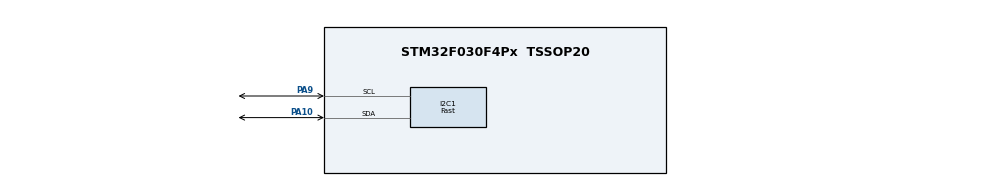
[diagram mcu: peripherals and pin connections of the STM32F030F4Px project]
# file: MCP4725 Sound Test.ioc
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I2C1.I2C_Speed_Mode=I2C_Fast
I2C1.Timing=0x0000020B
Mcu.Family=STM32F0
Mcu.Name=STM32F030F4Px
Mcu.Package=TSSOP20
PA10.Mode=I2C
PA10.Signal=I2C1_SDA
PA9.Mode=I2C
PA9.Signal=I2C1_SCL
ProjectManager.HeapSize=0x200
ProjectManager.StackSize=0x400
ProjectManager.TargetToolchain=SW4STM32
TIM3.Period=999
VP_TIM3_VS_ClockSourceINT.Mode=Internal
board=custom

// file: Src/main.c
/**
  ******************************************************************************
  * @file           : main.c
  * @brief          : Main program body
  ******************************************************************************
  ** This notice applies to any and all portions of this file
  * that are not between comment pairs USER CODE BEGIN and
  * USER CODE END. Other portions of this file, whether
  * inserted by the user or by software development tools
  * are owned by their respective copyright owners.
  *
  * COPYRIGHT(c) 2019 STMicroelectronics
  *
  * Redistribution and use in source and binary forms, with or without modification,
  * are permitted provided that the following conditions are met:
  *   1. Redistributions of source code must retain the above copyright notice,
  *      this list of conditions and the following disclaimer.
  *   2. Redistributions in binary form must reproduce the above copyright notice,
  *      this list of conditions and the following disclaimer in the documentation
  *      and/or other materials provided with the distribution.
  *   3. Neither the name of STMicroelectronics nor the names of its contributors
  *      may be used to endorse or promote products derived from this software
  *      without specific prior written permission.
  *
  * THIS SOFTWARE IS PROVIDED BY THE COPYRIGHT HOLDERS AND CONTRIBUTORS "AS IS"
  * AND ANY EXPRESS OR IMPLIED WARRANTIES, INCLUDING, BUT NOT LIMITED TO, THE
  * IMPLIED WARRANTIES OF MERCHANTABILITY AND FITNESS FOR A PARTICULAR PURPOSE ARE
  * DISCLAIMED. IN NO EVENT SHALL THE COPYRIGHT HOLDER OR CONTRIBUTORS BE LIABLE
  * FOR ANY DIRECT, INDIRECT, INCIDENTAL, SPECIAL, EXEMPLARY, OR CONSEQUENTIAL
  * DAMAGES (INCLUDING, BUT NOT LIMITED TO, PROCUREMENT OF SUBSTITUTE GOODS OR
  * SERVICES; LOSS OF USE, DATA, OR PROFITS; OR BUSINESS INTERRUPTION) HOWEVER
  * CAUSED AND ON ANY THEORY OF LIABILITY, WHETHER IN CONTRACT, STRICT LIABILITY,
  * OR TORT (INCLUDING NEGLIGENCE OR OTHERWISE) ARISING IN ANY WAY OUT OF THE USE
  * OF THIS SOFTWARE, EVEN IF ADVISED OF THE POSSIBILITY OF SUCH DAMAGE.
  *
  ******************************************************************************
  */
#include "main.h"
#include "stm32f0xx_hal.h"
#include "sounddata.h"

I2C_HandleTypeDef hi2c1;

TIM_HandleTypeDef htim3;

/* USER CODE BEGIN PV */
/* Private variables ---------------------------------------------------------*/

/* USER CODE END PV */

void SystemClock_Config(void);
static void MX_GPIO_Init(void);
static void MX_TIM3_Init(void);
static void MX_I2C1_Init(void);

/* USER CODE BEGIN PFP */
/* Private function prototypes -----------------------------------------------*/

/* USER CODE END PFP */

/* USER CODE BEGIN 0 */
unsigned char buffer[3];

void dacOutput(char eightBitValue)
{

	//int twelveBitValue = eightBitValue * ((1 << 12) - 1) / ((1 << 8) - 1);
	int twelveBitValue = eightBitValue << 4 | eightBitValue >> 4;
	buffer[0] = 0x40;
	buffer[1] = twelveBitValue>>4;
	buffer[2] = twelveBitValue<<4;
	HAL_I2C_Master_Transmit(&hi2c1, 0x61<<1, buffer, 3, 100);
}

/*
int state = 1;
int pos = 0;
size_t ledlength = sizeof(sounddata)/sizeof(sounddata[0]);

HAL_TIM_PeriodElapsedCallback(TIM_HandleTypeDef *htim)
{
	if (htim->Instance == TIM3)
	{
		if (state == 1)
		{
			if (pos < ledlength)
			{
				dacOutput(sounddata[pos]);
				pos++;
			}
			else
			{
				state = 0;
				pos = 0;
				dacOutput(0);
			}
		}
	}
}
*/
/* USER CODE END 0 */

int main(void)
{

  /* MCU Configuration----------------------------------------------------------*/

  /* Reset of all peripherals, Initializes the Flash interface and the Systick. */
  HAL_Init();

  /* Configure the system clock */
  SystemClock_Config();

  /* Initialize all configured peripherals */
  MX_GPIO_Init();
  MX_TIM3_Init();
  MX_I2C1_Init();
  /* USER CODE BEGIN 2 */
  int state = 1;
  int pos = 0;
  size_t ledlength = sizeof(sounddata)/sizeof(sounddata[0]);

  /* USER CODE END 2 */

  /* Infinite loop */
  /* USER CODE BEGIN WHILE */
  while (1)
  {
	  if (state == 1)
	    {
	  	  if (pos < ledlength)
	  	  {
	  		  dacOutput(sounddata[pos]);
	  		  pos++;
	  	  }
	  	  else
	  	  {
	  		  state = 0;
	  		  pos = 0;
	  		  //dacOutput(0);
	  	  }
	    }
  /* USER CODE END WHILE */

  }

}

void SystemClock_Config(void)
{

  RCC_OscInitTypeDef RCC_OscInitStruct;
  RCC_ClkInitTypeDef RCC_ClkInitStruct;
  RCC_PeriphCLKInitTypeDef PeriphClkInit;

    /**Initializes the CPU, AHB and APB busses clocks
    */
  RCC_OscInitStruct.OscillatorType = RCC_OSCILLATORTYPE_HSI;
  RCC_OscInitStruct.HSIState = RCC_HSI_ON;
  RCC_OscInitStruct.HSICalibrationValue = 16;
  RCC_OscInitStruct.PLL.PLLState = RCC_PLL_NONE;
  if (HAL_RCC_OscConfig(&RCC_OscInitStruct) != HAL_OK)
  {
    _Error_Handler(__FILE__, __LINE__);
  }

    /**Initializes the CPU, AHB and APB busses clocks
    */
  RCC_ClkInitStruct.ClockType = RCC_CLOCKTYPE_HCLK|RCC_CLOCKTYPE_SYSCLK
                              |RCC_CLOCKTYPE_PCLK1;
  RCC_ClkInitStruct.SYSCLKSource = RCC_SYSCLKSOURCE_HSI;
  RCC_ClkInitStruct.AHBCLKDivider = RCC_SYSCLK_DIV1;
  RCC_ClkInitStruct.APB1CLKDivider = RCC_HCLK_DIV1;

  if (HAL_RCC_ClockConfig(&RCC_ClkInitStruct, FLASH_LATENCY_0) != HAL_OK)
  {
    _Error_Handler(__FILE__, __LINE__);
  }

  PeriphClkInit.PeriphClockSelection = RCC_PERIPHCLK_I2C1;
  PeriphClkInit.I2c1ClockSelection = RCC_I2C1CLKSOURCE_HSI;
  if (HAL_RCCEx_PeriphCLKConfig(&PeriphClkInit) != HAL_OK)
  {
    _Error_Handler(__FILE__, __LINE__);
  }

    /**Configure the Systick interrupt time
    */
  HAL_SYSTICK_Config(HAL_RCC_GetHCLKFreq()/1000);

    /**Configure the Systick
    */
  HAL_SYSTICK_CLKSourceConfig(SYSTICK_CLKSOURCE_HCLK);

  /* SysTick_IRQn interrupt configuration */
  HAL_NVIC_SetPriority(SysTick_IRQn, 0, 0);
}

/* I2C1 init function */
static void MX_I2C1_Init(void)
{

  hi2c1.Instance = I2C1;
  hi2c1.Init.Timing = 0x0000020B;
  hi2c1.Init.OwnAddress1 = 0;
  hi2c1.Init.AddressingMode = I2C_ADDRESSINGMODE_7BIT;
  hi2c1.Init.DualAddressMode = I2C_DUALADDRESS_DISABLE;
  hi2c1.Init.OwnAddress2 = 0;
  hi2c1.Init.OwnAddress2Masks = I2C_OA2_NOMASK;
  hi2c1.Init.GeneralCallMode = I2C_GENERALCALL_DISABLE;
  hi2c1.Init.NoStretchMode = I2C_NOSTRETCH_DISABLE;
  if (HAL_I2C_Init(&hi2c1) != HAL_OK)
  {
    _Error_Handler(__FILE__, __LINE__);
  }

    /**Configure Analogue filter
    */
  if (HAL_I2CEx_ConfigAnalogFilter(&hi2c1, I2C_ANALOGFILTER_ENABLE) != HAL_OK)
  {
    _Error_Handler(__FILE__, __LINE__);
  }

    /**Configure Digital filter
    */
  if (HAL_I2CEx_ConfigDigitalFilter(&hi2c1, 0) != HAL_OK)
  {
    _Error_Handler(__FILE__, __LINE__);
  }

}

/* TIM3 init function */
static void MX_TIM3_Init(void)
{

  TIM_ClockConfigTypeDef sClockSourceConfig;
  TIM_MasterConfigTypeDef sMasterConfig;

  htim3.Instance = TIM3;
  htim3.Init.Prescaler = 0;
  htim3.Init.CounterMode = TIM_COUNTERMODE_UP;
  htim3.Init.Period = 999;
  htim3.Init.ClockDivision = TIM_CLOCKDIVISION_DIV1;
  htim3.Init.AutoReloadPreload = TIM_AUTORELOAD_PRELOAD_DISABLE;
  if (HAL_TIM_Base_Init(&htim3) != HAL_OK)
  {
    _Error_Handler(__FILE__, __LINE__);
  }

  sClockSourceConfig.ClockSource = TIM_CLOCKSOURCE_INTERNAL;
  if (HAL_TIM_ConfigClockSource(&htim3, &sClockSourceConfig) != HAL_OK)
  {
    _Error_Handler(__FILE__, __LINE__);
  }

  sMasterConfig.MasterOutputTrigger = TIM_TRGO_RESET;
  sMasterConfig.MasterSlaveMode = TIM_MASTERSLAVEMODE_DISABLE;
  if (HAL_TIMEx_MasterConfigSynchronization(&htim3, &sMasterConfig) != HAL_OK)
  {
    _Error_Handler(__FILE__, __LINE__);
  }

}

/** Pinout Configuration
*/
static void MX_GPIO_Init(void)
{

  /* GPIO Ports Clock Enable */
  __HAL_RCC_GPIOA_CLK_ENABLE();

}

void _Error_Handler(char *file, int line)
{
  while(1)
  {
  }
}

/************************ (C) COPYRIGHT STMicroelectronics *****END OF FILE****/
